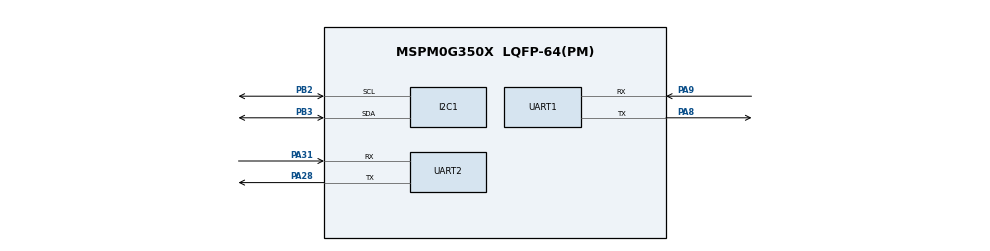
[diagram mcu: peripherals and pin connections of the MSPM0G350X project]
/**
 *
 * @cliArgs --device "MSPM0G350X" --part "Default" --package "LQFP-64(PM)" --product "mspm0_sdk@2.11.00.07"
 * @versions {"tool":"1.28.0+4696"}
 */

/**
 * Import the modules used in this configuration.
 */
const I2C    = scripting.addModule("/ti/driverlib/I2C", {}, false);
const I2C1   = I2C.addInstance();
const SYSCTL = scripting.addModule("/ti/driverlib/SYSCTL");
const UART   = scripting.addModule("/ti/driverlib/UART", {}, false);
const UART1  = UART.addInstance();
const UART2  = UART.addInstance();

/**
 * Write custom configuration values to the imported modules.
 */
I2C1.$name                           = "I2C_0";
I2C1.basicEnableController           = true;
I2C1.basicControllerStandardBusSpeed = "Fast";
I2C1.intController                   = ["TXFIFO_TRIGGER","TX_DONE"];
I2C1.peripheral.$assign              = "I2C1";
I2C1.peripheral.sdaPin.$assign       = "PB3";
I2C1.peripheral.sclPin.$assign       = "PB2";
I2C1.sdaPinConfig.$name              = "ti_driverlib_gpio_GPIOPinGeneric0";
I2C1.sclPinConfig.$name              = "ti_driverlib_gpio_GPIOPinGeneric1";

const Board = scripting.addModule("/ti/driverlib/Board", {}, false);

SYSCTL.forceDefaultClkConfig = true;

UART1.targetBaudRate                   = 115200;
UART1.enabledInterrupts                = ["RX"];
UART1.$name                            = "UART1_PAN";
UART1.peripheral.$assign               = "UART1";
UART1.peripheral.rxPin.$assign         = "PA9";
UART1.peripheral.txPin.$assign         = "PA8";
UART1.txPinConfig.$name                = "ti_driverlib_gpio_GPIOPinGeneric2";
UART1.txPinConfig.direction            = scripting.forceWrite("OUTPUT");
UART1.txPinConfig.hideOutputInversion  = scripting.forceWrite(false);
UART1.txPinConfig.onlyInternalResistor = scripting.forceWrite(false);
UART1.txPinConfig.passedPeripheralType = scripting.forceWrite("Digital");
UART1.rxPinConfig.$name                = "ti_driverlib_gpio_GPIOPinGeneric3";
UART1.rxPinConfig.hideOutputInversion  = scripting.forceWrite(false);
UART1.rxPinConfig.onlyInternalResistor = scripting.forceWrite(false);
UART1.rxPinConfig.passedPeripheralType = scripting.forceWrite("Digital");

UART2.$name                            = "UART0_TILT";
UART2.targetBaudRate                   = 115200;
UART2.enabledInterrupts                = ["RX"];
UART2.peripheral.rxPin.$assign         = "PA31";
UART2.peripheral.txPin.$assign         = "PA28";
UART2.txPinConfig.$name                = "ti_driverlib_gpio_GPIOPinGeneric4";
UART2.txPinConfig.direction            = scripting.forceWrite("OUTPUT");
UART2.txPinConfig.hideOutputInversion  = scripting.forceWrite(false);
UART2.txPinConfig.onlyInternalResistor = scripting.forceWrite(false);
UART2.txPinConfig.passedPeripheralType = scripting.forceWrite("Digital");
UART2.rxPinConfig.$name                = "ti_driverlib_gpio_GPIOPinGeneric5";
UART2.rxPinConfig.hideOutputInversion  = scripting.forceWrite(false);
UART2.rxPinConfig.onlyInternalResistor = scripting.forceWrite(false);
UART2.rxPinConfig.passedPeripheralType = scripting.forceWrite("Digital");

/**
 * Pinmux solution for unlocked pins/peripherals. This ensures that minor changes to the automatic solver in a future
 * version of the tool will not impact the pinmux you originally saw.  These lines can be completely deleted in order to
 * re-solve from scratch.
 */
Board.peripheral.$suggestSolution          = "DEBUGSS";
Board.peripheral.swclkPin.$suggestSolution = "PA20";
Board.peripheral.swdioPin.$suggestSolution = "PA19";
SYSCTL.peripheral.$suggestSolution         = "SYSCTL";
UART2.peripheral.$suggestSolution          = "UART0";
